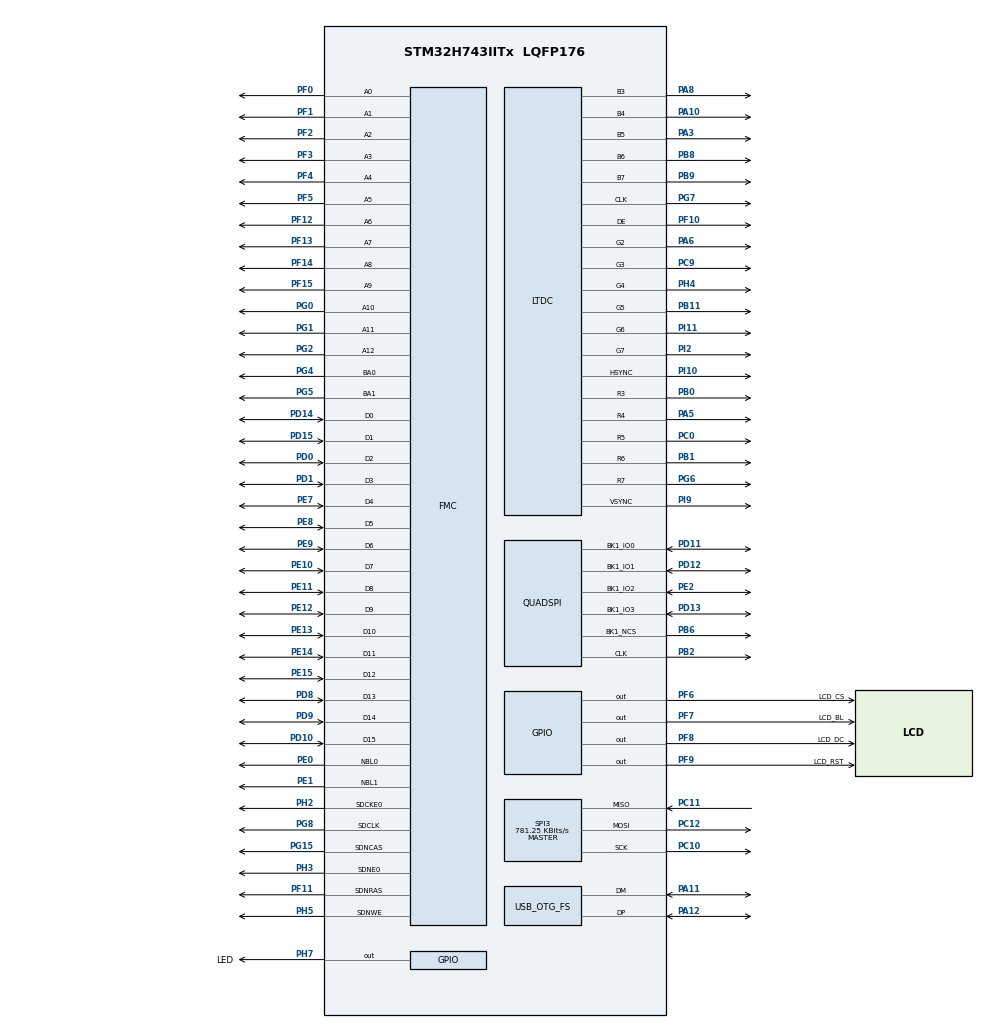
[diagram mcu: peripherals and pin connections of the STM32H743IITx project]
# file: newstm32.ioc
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CORTEX_M7.AccessPermission_Spec=MPU_REGION_FULL_ACCESS
CORTEX_M7.BaseAddress_Spec=0xC0000000
CORTEX_M7.CPU_DCache=Enabled
CORTEX_M7.CPU_ICache=Enabled
CORTEX_M7.DisableExec_Spec=MPU_INSTRUCTION_ACCESS_ENABLE
CORTEX_M7.IsBufferable_Spec=MPU_ACCESS_BUFFERABLE
CORTEX_M7.IsCacheable_Spec=MPU_ACCESS_CACHEABLE
CORTEX_M7.IsShareable_Spec=MPU_ACCESS_NOT_SHAREABLE
CORTEX_M7.Size_Spec=MPU_REGION_SIZE_32MB
CORTEX_M7.SubRegionDisable_Spec=0x0
CORTEX_M7.default_mode_Activation=1
FMC.CASLatency1=FMC_SDRAM_CAS_LATENCY_3
FMC.ExitSelfRefreshDelay1=10
FMC.LoadToActiveDelay1=2
FMC.RCDDelay1=3
FMC.RPDelay1=3
FMC.ReadBurst1=FMC_SDRAM_RBURST_ENABLE
FMC.ReadPipeDelay1=FMC_SDRAM_RPIPE_DELAY_2
FMC.RowCycleDelay1=9
FMC.SDClockPeriod1=FMC_SDRAM_CLOCK_PERIOD_3
FMC.SDClockPeriod2=FMC_SDRAM_CLOCK_PERIOD_3
FMC.SelfRefreshTime1=6
FMC.WriteRecoveryTime1=4
LTDC.ActiveW=320
LTDC.Alpha0_L0=255
LTDC.Alpha_L0=255
LTDC.FBStartAdress_L0=0xC0000000
LTDC.HBP=3
LTDC.HFP=3
LTDC.HSync=3
LTDC.ImageHeight_L0=480
LTDC.ImageWidth_L0=320
LTDC.Layers=0
LTDC.PCPolarity=LTDC_PCPOLARITY_IIPC
LTDC.PixelFormat_L0=LTDC_PIXEL_FORMAT_RGB565
LTDC.VSync=1
LTDC.WindowX1_L0=320
LTDC.WindowY1_L0=480
Mcu.Family=STM32H7
Mcu.Name=STM32H743IITx
Mcu.Package=LQFP176
NVIC.LTDC_IRQn=true\:0\:0\:false\:false\:true\:true\:true\:true
NVIC.OTG_FS_IRQn=true\:0\:0\:false\:false\:true\:false\:true\:true
NVIC.PriorityGroup=NVIC_PRIORITYGROUP_4
PA10.GPIO_Speed=GPIO_SPEED_FREQ_VERY_HIGH
PA10.Mode=RGB565
PA10.Signal=LTDC_B4
PA11.Mode=Device_Only
PA11.Signal=USB_OTG_FS_DM
PA12.Mode=Device_Only
PA12.Signal=USB_OTG_FS_DP
PA3.GPIO_Speed=GPIO_SPEED_FREQ_VERY_HIGH
PA3.Mode=RGB565
PA3.Signal=LTDC_B5
PA5.GPIO_Speed=GPIO_SPEED_FREQ_VERY_HIGH
PA5.Mode=RGB565
PA5.Signal=LTDC_R4
PA6.GPIO_Speed=GPIO_SPEED_FREQ_VERY_HIGH
PA6.Mode=RGB565
PA6.Signal=LTDC_G2
PA8.GPIO_Speed=GPIO_SPEED_FREQ_VERY_HIGH
PA8.Mode=RGB565
PA8.Signal=LTDC_B3
PB0.GPIO_Speed=GPIO_SPEED_FREQ_VERY_HIGH
PB0.Mode=RGB565
PB0.Signal=LTDC_R3
PB1.GPIO_Speed=GPIO_SPEED_FREQ_VERY_HIGH
PB1.Mode=RGB565
PB1.Signal=LTDC_R6
PB11.GPIO_Speed=GPIO_SPEED_FREQ_VERY_HIGH
PB11.Mode=RGB565
PB11.Signal=LTDC_G5
PB2.GPIO_Speed=GPIO_SPEED_FREQ_VERY_HIGH
PB2.Mode=Single Bank 1
PB2.Signal=QUADSPI_CLK
PB6.GPIO_Speed=GPIO_SPEED_FREQ_VERY_HIGH
PB6.Mode=Single Bank 1
PB6.Signal=QUADSPI_BK1_NCS
PB8.GPIO_Speed=GPIO_SPEED_FREQ_VERY_HIGH
PB8.Mode=RGB565
PB8.Signal=LTDC_B6
PB9.GPIO_Speed=GPIO_SPEED_FREQ_VERY_HIGH
PB9.Mode=RGB565
PB9.Signal=LTDC_B7
PC0.GPIO_Speed=GPIO_SPEED_FREQ_VERY_HIGH
PC0.Mode=RGB565
PC0.Signal=LTDC_R5
PC10.Mode=Full_Duplex_Master
PC10.Signal=SPI3_SCK
PC11.Mode=Full_Duplex_Master
PC11.Signal=SPI3_MISO
PC12.Mode=Full_Duplex_Master
PC12.Signal=SPI3_MOSI
PC14-OSC32_IN\ (OSC32_IN).Mode=LSE-External-Oscillator
PC14-OSC32_IN\ (OSC32_IN).Signal=RCC_OSC32_IN
PC15-OSC32_OUT\ (OSC32_OUT).Mode=LSE-External-Oscillator
PC15-OSC32_OUT\ (OSC32_OUT).Signal=RCC_OSC32_OUT
PC9.GPIO_Speed=GPIO_SPEED_FREQ_VERY_HIGH
PC9.Mode=RGB565
PC9.Signal=LTDC_G3
PD0.Signal=FMC_D2_DA2
PD1.Signal=FMC_D3_DA3
PD10.Signal=FMC_D15_DA15
PD11.GPIO_Speed=GPIO_SPEED_FREQ_VERY_HIGH
PD11.Mode=Single Bank 1
PD11.Signal=QUADSPI_BK1_IO0
PD12.GPIO_Speed=GPIO_SPEED_FREQ_VERY_HIGH
PD12.Mode=Single Bank 1
PD12.Signal=QUADSPI_BK1_IO1
PD13.GPIO_Speed=GPIO_SPEED_FREQ_VERY_HIGH
PD13.Mode=Single Bank 1
PD13.Signal=QUADSPI_BK1_IO3
PD14.Signal=FMC_D0_DA0
PD15.Signal=FMC_D1_DA1
PD8.Signal=FMC_D13_DA13
PD9.Signal=FMC_D14_DA14
PE0.Signal=FMC_NBL0
PE1.Signal=FMC_NBL1
PE10.Signal=FMC_D7_DA7
PE11.Signal=FMC_D8_DA8
PE12.Signal=FMC_D9_DA9
PE13.Signal=FMC_D10_DA10
PE14.Signal=FMC_D11_DA11
PE15.Signal=FMC_D12_DA12
PE2.GPIO_Speed=GPIO_SPEED_FREQ_VERY_HIGH
PE2.Mode=Single Bank 1
PE2.Signal=QUADSPI_BK1_IO2
PE7.Signal=FMC_D4_DA4
PE8.Signal=FMC_D5_DA5
PE9.Signal=FMC_D6_DA6
PF0.Signal=FMC_A0
PF1.Signal=FMC_A1
PF10.GPIO_Speed=GPIO_SPEED_FREQ_VERY_HIGH
PF10.Mode=RGB565
PF10.Signal=LTDC_DE
PF11.Signal=FMC_SDNRAS
PF12.Signal=FMC_A6
PF13.Signal=FMC_A7
PF14.Signal=FMC_A8
PF15.Signal=FMC_A9
PF2.Signal=FMC_A2
PF3.Signal=FMC_A3
PF4.Signal=FMC_A4
PF5.Signal=FMC_A5
PF6.GPIO_Label=LCD_CS
PF6.GPIO_Speed=GPIO_SPEED_FREQ_VERY_HIGH
PF6.Signal=GPIO_Output
PF7.GPIO_Label=LCD_BL
PF7.GPIO_Speed=GPIO_SPEED_FREQ_VERY_HIGH
PF7.PinState=GPIO_PIN_SET
PF7.Signal=GPIO_Output
PF8.GPIO_Label=LCD_DC
PF8.GPIO_Speed=GPIO_SPEED_FREQ_VERY_HIGH
PF8.Signal=GPIO_Output
PF9.GPIO_Label=LCD_RST
PF9.GPIO_Speed=GPIO_SPEED_FREQ_VERY_HIGH
PF9.Signal=GPIO_Output
PG0.Signal=FMC_A10
PG1.Signal=FMC_A11
PG15.Signal=FMC_SDNCAS
PG2.Signal=FMC_A12
PG4.Signal=FMC_A14_BA0
PG5.Signal=FMC_A15_BA1
PG6.GPIO_Speed=GPIO_SPEED_FREQ_VERY_HIGH
PG6.Mode=RGB565
PG6.Signal=LTDC_R7
PG7.GPIO_Speed=GPIO_SPEED_FREQ_VERY_HIGH
PG7.Mode=RGB565
PG7.Signal=LTDC_CLK
PG8.Signal=FMC_SDCLK
PH0-OSC_IN\ (PH0).Mode=HSE-External-Oscillator
PH0-OSC_IN\ (PH0).Signal=RCC_OSC_IN
PH1-OSC_OUT\ (PH1).Mode=HSE-External-Oscillator
PH1-OSC_OUT\ (PH1).Signal=RCC_OSC_OUT
PH2.Mode=SdramChipSelect1_1
PH2.Signal=FMC_SDCKE0
PH3.Mode=SdramChipSelect1_1
PH3.Signal=FMC_SDNE0
PH4.GPIO_Speed=GPIO_SPEED_FREQ_VERY_HIGH
PH4.Mode=RGB565
PH4.Signal=LTDC_G4
PH5.Signal=FMC_SDNWE
PH7.GPIO_Label=LED
PH7.PinState=GPIO_PIN_SET
PH7.Signal=GPIO_Output
PI10.GPIO_Speed=GPIO_SPEED_FREQ_VERY_HIGH
PI10.Mode=RGB565
PI10.Signal=LTDC_HSYNC
PI11.GPIO_Speed=GPIO_SPEED_FREQ_VERY_HIGH
PI11.Mode=RGB565
PI11.Signal=LTDC_G6
PI2.GPIO_Speed=GPIO_SPEED_FREQ_VERY_HIGH
PI2.Mode=RGB565
PI2.Signal=LTDC_G7
PI9.GPIO_Speed=GPIO_SPEED_FREQ_VERY_HIGH
PI9.Mode=RGB565
PI9.Signal=LTDC_VSYNC
ProjectManager.HeapSize=0x2000
ProjectManager.StackSize=0x4000
ProjectManager.TargetToolchain=CMake
RCC.ADCFreq_Value=125000000
RCC.APB1Freq_Value=100000000
RCC.APB2Freq_Value=100000000
RCC.APB3Freq_Value=100000000
RCC.APB4Freq_Value=100000000
RCC.CortexFreq_Value=400000000
RCC.D1PPRE=RCC_APB3_DIV2
RCC.D2PPRE1=RCC_APB1_DIV2
RCC.D2PPRE2=RCC_APB2_DIV2
RCC.D3PPRE=RCC_APB4_DIV2
RCC.DIVM1=2
RCC.DIVM2=2
RCC.DIVM3=1
RCC.DIVN1=64
RCC.DIVN2=20
RCC.DIVN3=6
RCC.DIVQ1=4
RCC.DIVR3=15
RCC.FMCCLockSelection=RCC_FMCCLKSOURCE_PLL2
RCC.HCLKFreq_Value=200000000
RCC.HPRE=RCC_HCLK_DIV2
RCC.PLL2FRACN=0
RCC.PLL3FRACN=0
RCC.PLLFRACN=0
RCC.PLLSourceVirtual=RCC_PLLSOURCE_HSE
RCC.SYSCLKFreq_VALUE=400000000
RCC.SYSCLKSource=RCC_SYSCLKSOURCE_PLLCLK
RCC.USBCLockSelection=RCC_USBCLKSOURCE_HSI48
RCC.USBFreq_Value=48000000
SH.FMC_A0.0=FMC_A0,13b-sda1
SH.FMC_A1.0=FMC_A1,13b-sda1
SH.FMC_A10.0=FMC_A10,13b-sda1
SH.FMC_A11.0=FMC_A11,13b-sda1
SH.FMC_A12.0=FMC_A12,13b-sda1
SH.FMC_A14_BA0.0=FMC_BA0,FourSdramBanks1
SH.FMC_A15_BA1.0=FMC_BA1,FourSdramBanks1
SH.FMC_A2.0=FMC_A2,13b-sda1
SH.FMC_A3.0=FMC_A3,13b-sda1
SH.FMC_A4.0=FMC_A4,13b-sda1
SH.FMC_A5.0=FMC_A5,13b-sda1
SH.FMC_A6.0=FMC_A6,13b-sda1
SH.FMC_A7.0=FMC_A7,13b-sda1
SH.FMC_A8.0=FMC_A8,13b-sda1
SH.FMC_A9.0=FMC_A9,13b-sda1
SH.FMC_D0_DA0.0=FMC_D0,sd-16b-d1
SH.FMC_D10_DA10.0=FMC_D10,sd-16b-d1
SH.FMC_D11_DA11.0=FMC_D11,sd-16b-d1
SH.FMC_D12_DA12.0=FMC_D12,sd-16b-d1
SH.FMC_D13_DA13.0=FMC_D13,sd-16b-d1
SH.FMC_D14_DA14.0=FMC_D14,sd-16b-d1
SH.FMC_D15_DA15.0=FMC_D15,sd-16b-d1
SH.FMC_D1_DA1.0=FMC_D1,sd-16b-d1
SH.FMC_D2_DA2.0=FMC_D2,sd-16b-d1
SH.FMC_D3_DA3.0=FMC_D3,sd-16b-d1
SH.FMC_D4_DA4.0=FMC_D4,sd-16b-d1
SH.FMC_D5_DA5.0=FMC_D5,sd-16b-d1
SH.FMC_D6_DA6.0=FMC_D6,sd-16b-d1
SH.FMC_D7_DA7.0=FMC_D7,sd-16b-d1
SH.FMC_D8_DA8.0=FMC_D8,sd-16b-d1
SH.FMC_D9_DA9.0=FMC_D9,sd-16b-d1
SH.FMC_NBL0.0=FMC_NBL0,Sd2ByteEnable1
SH.FMC_NBL1.0=FMC_NBL1,Sd2ByteEnable1
SH.FMC_SDCLK.0=FMC_SDCLK,13b-sda1
SH.FMC_SDNCAS.0=FMC_SDNCAS,13b-sda1
SH.FMC_SDNRAS.0=FMC_SDNRAS,13b-sda1
SH.FMC_SDNWE.0=FMC_SDNWE,13b-sda1
SPI3.BaudRatePrescaler=SPI_BAUDRATEPRESCALER_256
SPI3.CalculateBaudRate=781.25 KBits/s
SPI3.DataSize=SPI_DATASIZE_8BIT
SPI3.Direction=SPI_DIRECTION_2LINES
SPI3.Mode=SPI_MODE_MASTER
SPI3.NSSPMode=SPI_NSS_PULSE_DISABLE
SPI3.VirtualType=VM_MASTER
USB_DEVICE.CLASS_NAME_FS=CDC
USB_DEVICE.VirtualMode-CDC_FS=Cdc
USB_DEVICE.VirtualModeFS=Cdc_FS
USB_OTG_FS.VirtualMode=Device_Only
VP_MEMORYMAP_VS_MEMORYMAP.Mode=CurAppReg
VP_USB_DEVICE_VS_USB_DEVICE_CDC_FS.Mode=CDC_FS
board=custom

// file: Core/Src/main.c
/* USER CODE BEGIN Header */
/**
 ******************************************************************************
 * @file           : main.c
 * @brief          : Main program body
 ******************************************************************************
 * @attention
 *
 * Copyright (c) 2026 STMicroelectronics.
 * All rights reserved.
 *
 * This software is licensed under terms that can be found in the LICENSE file
 * in the root directory of this software component.
 * If no LICENSE file comes with this software, it is provided AS-IS.
 *
 ******************************************************************************
 */
/* USER CODE END Header */
#include "main.h"
#include "ltdc.h"
#include "quadspi.h"
#include "spi.h"
#include "stm32h7xx_hal.h"
#include "usb_device.h"
#include "gpio.h"
#include "fmc.h"

/* USER CODE BEGIN Includes */
#include "usbd_cdc_if.h"
#include <stdio.h>
#include <string.h>
#include "sdram_util.h"
/* USER CODE END Includes */

/* USER CODE BEGIN PD */

uint16_t *frame_buffers[2] = {
    (uint16_t *)(SDRAM_BASE),                                 // FB1
    (uint16_t *)(SDRAM_BASE + (LCD_WIDTH * LCD_HEIGHT * 2))   // FB2
};

extern void pixmap8x16(uint16_t color, void *out_fb, void *pixmap);
extern void pixmap8x8(uint16_t color, void *out_fb, void *pixmap);

uint8_t current_buffer = 0; // Какой буфер сейчас рисуем

int cursor_x = 0;
int cursor_y = 0;

#include <stdint.h>

#define FB_W 480u
#define FB_H 320u

static inline void dma2d_init_once(void)
{
    // DMA2D clock enable (на H7 это AHB3)
    RCC->AHB3ENR |= RCC_AHB3ENR_DMA2DEN;
    (void)RCC->AHB3ENR; // небольшая задержка на запись

    // На всякий: сбросить/очистить флаги
    DMA2D->CR = 0;
    DMA2D->IFCR = 0x3F; // CTC|CCE|CTE|CAE|CTW|CL
}

static inline void dma2d_fill_rgb565(uint16_t *fb,
                                     uint16_t color,
                                     uint32_t width,
                                     uint32_t height,
                                     uint32_t stride_pixels) // обычно = width
{
    // Ждём, если DMA2D занят
    while (DMA2D->CR & DMA2D_CR_START) { /* spin */ }

    // Очистить флаги
    DMA2D->IFCR = 0x3F;

    // Режим: Register-to-Memory
    DMA2D->CR = (DMA2D->CR & ~DMA2D_CR_MODE) | (0x3u << DMA2D_CR_MODE_Pos);

    // Куда пишем
    DMA2D->OMAR = (uint32_t)fb;

    // Формат выхода: RGB565 (в DMA2D это обычно "2")
    // В H7: 0=ARGB8888, 1=RGB888, 2=RGB565, 3=ARGB1555, 4=ARGB4444
    DMA2D->OPFCCR = 2u;

    // Цвет (для RGB565 достаточно младших 16 бит)
    DMA2D->OCOLR = (uint32_t)color;

    // Output offset: сколько пикселей пропустить в конце каждой строки
    // (stride - width) в ПИКСЕЛЯХ, не в байтах
    DMA2D->OOR = (stride_pixels - width);

    // Размер: NLR = (pixels per line) | (number of lines << 16)
    DMA2D->NLR = (width & 0x3FFFu) | ((height & 0x3FFFu) << 16);

    // Старт
    DMA2D->CR |= DMA2D_CR_START;

    // Ждём завершение (можно и по IRQ)
    while ((DMA2D->ISR & DMA2D_ISR_TCIF) == 0) { /* spin */ }

    // Сбросить TC флаг
    DMA2D->IFCR = DMA2D_IFCR_CTCIF;

    __asm__ volatile("dsb 0xF" ::: "memory"); // чтобы записи точно “дошли” до SDRAM
}

static inline void screen_clear(uint16_t *fb, uint16_t color)
{
    // Пишем 32-битными словами: 0xCCCCCCCC где C = RGB565
    uint32_t *p   = (uint32_t*)fb;
    uint32_t pat  = (uint32_t)color | ((uint32_t)color << 16);

    // 4x stm {r0-r7} = 4 * 8 * 4 = 128 байт за итерацию
    uint32_t cnt  = (FB_W * FB_H * 2u) / 128u;   // для 480x320 => 2400

    __asm__ volatile(
        "mov    r0, %[pat]          \n\t"
        "mov    r1, r0              \n\t"
        "mov    r2, r0              \n\t"
        "mov    r3, r0              \n\t"
        "mov    r4, r0              \n\t"
        "mov    r5, r0              \n\t"
        "mov    r6, r0              \n\t"
        "mov    r7, r0              \n\t"
        "1:                         \n\t"
        "stmia  %[p]!, {r0-r7}      \n\t"
        "stmia  %[p]!, {r0-r7}      \n\t"
        "stmia  %[p]!, {r0-r7}      \n\t"
        "stmia  %[p]!, {r0-r7}      \n\t"
        "subs   %[cnt], %[cnt], #1  \n\t"
        "bne    1b                  \n\t"
        : [p]   "+r"(p),
          [cnt] "+r"(cnt)
        : [pat] "r"(pat)
        : "r0","r1","r2","r3","r4","r5","r6","r7","cc","memory"
    );

    // Для внешней памяти (FMC/SDRAM) часто полезно:
    __asm__ volatile("dsb 0xF" ::: "memory");   // __DSB();
}

/* USER CODE END PD */

void SystemClock_Config(void);
static void MPU_Config(void);
/* USER CODE BEGIN PFP */

void draw_rect(uint16_t *fb,int x, int y, int w, int h, uint16_t color) {

    for (int i = y; i < y + h; i++) {
        // Если строка вне экрана — пропускаем её
        if (i < 0 || i >= 480) continue;

        for (int j = x; j < x + w; j++) {
            // Если пиксель вне строки — пропускаем его
            if (j < 0 || j >= 320) continue;

            fb[i * 320 + j] = color;
        }
    }
}

void draw_char(uint16_t *fb, int x, int y, uint16_t color, uint8_t ch) {
    // Используем твои объявленные переменные
    // Смещение: каждый символ в 8x16 занимает ровно 16 байт
    const uint8_t *char_ptr = &fnt_wang_8x16[ch * 16];

    for (int i = 0; i < 16; i++) {
        uint8_t row = char_ptr[i];

        // Рисуем строку из 8 пикселей
        for (int bit = 0; bit < 8; bit++) {
            // Если бит установлен — рисуем пиксель цвета color
            // Если нет — ничего не делаем (прозрачный фон)
            if (row & (0x80 >> bit)) {
                // ВАЖНО: Проверь, что LCD_WIDTH равен Active Width из настроек LTDC
                fb[(y + i) * 320 -1 + (x + bit)] = color;
            }
        }
    }
}

void print_string(uint16_t *fb, int x, int y, uint16_t color, const char *str) {
    int cur_x = x;
    int cur_y = y;

    while (*str) {
        // 1. Проверяем на символ новой строки
        if (*str == '\n') {
            cur_x = x;      // Возвращаемся к начальному X
            cur_y += 16;    // Переходим на 16 пикселей вниз
            str++;
            continue;
        }

        // 2. Проверяем, не вылезем ли мы за край экрана (320 пикселей)
        if (cur_x > 320 - 8) {
            cur_x = x;      // Перенос по достижении края
            cur_y += 16;
        }

        // 3. Проверяем, не вылезем ли за нижний край (480 пикселей)
        if (cur_y > 480 - 16) {
            break; // Экран кончился
        }

        // 4. Рисуем символ
        draw_char(fb, cur_x, cur_y, color, (uint8_t)*str);

        // 5. Сдвигаемся вправо и к следующему символу
        cur_x += 8;
        str++;
    }
}

/* USER CODE END PFP */

int main(void)
{

  /* MPU Configuration--------------------------------------------------------*/
  MPU_Config();

  /* Enable the CPU Cache */

  /* Enable I-Cache---------------------------------------------------------*/
  //SCB_EnableICache();

  /* Enable D-Cache---------------------------------------------------------*/
 // SCB_EnableDCache();

  /* MCU Configuration--------------------------------------------------------*/

  /* Reset of all peripherals, Initializes the Flash interface and the Systick. */
  HAL_Init();

  /* Configure the system clock */
  SystemClock_Config();

  /* Initialize all configured peripherals */
  MX_GPIO_Init();
  MX_FMC_Init();
  MX_QUADSPI_Init();
  MX_SPI3_Init();
  MX_USB_DEVICE_Init();
  /* USER CODE BEGIN 2 */
	SDRAM_Init_All(&hsdram1);

	HAL_GPIO_WritePin(LCD_RST_GPIO_Port, LCD_RST_Pin, GPIO_PIN_RESET);
	HAL_Delay(50);
	HAL_GPIO_WritePin(LCD_RST_GPIO_Port, LCD_RST_Pin, GPIO_PIN_SET);
	HAL_Delay(150);
	HAL_GPIO_WritePin(LCD_BL_GPIO_Port, LCD_BL_Pin, GPIO_PIN_SET);
	ILI9844_SPI_init();
	MX_LTDC_Init();

	LTDC_LayerCfgTypeDef pLayerCfg = {0};

	// Окно отрисовки (весь экран)
	pLayerCfg.WindowX0 = 0;
	pLayerCfg.WindowX1 = 320; // Ширина
	pLayerCfg.WindowY0 = 0;
	pLayerCfg.WindowY1 = 480; // Высота

	pLayerCfg.PixelFormat = LTDC_PIXEL_FORMAT_RGB565;
	pLayerCfg.Alpha = 255;
	pLayerCfg.Alpha0 = 255; // Обычно фон прозрачный, если слой перекрывает его

	// Правильные факторы смешивания для непрозрачного слоя
	pLayerCfg.BlendingFactor1 = LTDC_BLENDING_FACTOR1_PAxCA;
	pLayerCfg.BlendingFactor2 = LTDC_BLENDING_FACTOR2_PAxCA;

	// Твой проверенный адрес в SDRAM!
	pLayerCfg.FBStartAdress = (uint32_t)frame_buffers[current_buffer];

	pLayerCfg.ImageWidth = 320;
	pLayerCfg.ImageHeight = 480;

	pLayerCfg.Backcolor.Blue = 0;
	pLayerCfg.Backcolor.Green = 0;
	pLayerCfg.Backcolor.Red = 0;

	HAL_LTDC_ConfigLayer(&hltdc, &pLayerCfg, 0);
	// Применяем настройки
	HAL_LTDC_Reload(&hltdc, LTDC_RELOAD_IMMEDIATE);

	//  fb_fill(0x001F);
	// Даем USB пару секунд, чтобы Windows его точно увидела

  /* USER CODE END 2 */

  /* Infinite loop */
  /* USER CODE BEGIN WHILE */

int rect_size = 40;
 uint16_t *draw_fb1 = frame_buffers[0];
    memset(draw_fb1, 0, 320 * 480 * 2);
     uint16_t *draw_fb2 = frame_buffers[1];
    memset(draw_fb2, 0, 320 * 480 * 2);

    uint16_t color = 0xF800; // Красный (RGB565)
    int x = 10;
    int y = 10;
    int dx = 1;
    int dy = 1;

while (1) {
    // 1. Выбираем буфер, который сейчас НЕ отображается (Back Buffer)
    uint8_t back_idx = !current_buffer;
    uint16_t *draw_fb = frame_buffers[back_idx];

    // 2. Очистка экрана (чтобы текст не накладывался друг на друга)
    // Используем memset (быстрее) или простой цикл
   // memset(draw_fb, 0, LCD_WIDTH * LCD_HEIGHT * 2);
//screen_clear(draw_fb, 0x0000);

dma2d_init_once();
dma2d_fill_rgb565(draw_fb, 0x0000, 480, 320, 480);

if (x + rect_size >= LCD_HEIGHT-1 || x <= 0) {
        dx = -dx; // Меняем направление по X
    }
    x += dx;

    if (y + rect_size >= LCD_WIDTH-1 || y <= 0) {
        dy = -dy; // Меняем направление по Y
    }
    y += dy;

draw_rect(draw_fb, x, y, rect_size, rect_size, color);

    // draw_char(draw_fb, 100, 100, 0x07E0, 87);
    // draw_char(draw_fb, 100+8, 100, 0x07E0, 88);
    print_string(draw_fb, 50, 50, 0x07E0, "Hello, STM32H7!\nThis is a test of\nLTDC with double buffering.\nEnjoy coding!");

    // 4. СБРОС КЭША (КРИТИЧНО для STM32H7)
    // CPU записал данные в кэш, нужно вытолкнуть их в SDRAM, чтобы LTDC их увидел
  //  SCB_CleanDCache_by_Addr((uint32_t *)draw_fb, LCD_WIDTH * LCD_HEIGHT * 2);

    // 5. Переключаем адрес в LTDC
    HAL_LTDC_SetAddress_NoReload(&hltdc, (uint32_t)draw_fb, 0);
    HAL_LTDC_Reload(&hltdc, LTDC_RELOAD_VERTICAL_BLANKING);

    // 6. Ждем завершения VSync (когда адрес реально применится)
    while ((hltdc.Instance->SRCR & LTDC_RELOAD_VERTICAL_BLANKING) != 0);

    // 7. Меняем индекс для следующей итерации
    current_buffer = back_idx;

   // HAL_Delay(100);
}
  /* USER CODE END 3 */
}

void SystemClock_Config(void)
{
  RCC_OscInitTypeDef RCC_OscInitStruct = {0};
  RCC_ClkInitTypeDef RCC_ClkInitStruct = {0};

  /** Supply configuration update enable
  */
  HAL_PWREx_ConfigSupply(PWR_LDO_SUPPLY);

  /** Configure the main internal regulator output voltage
  */
  __HAL_PWR_VOLTAGESCALING_CONFIG(PWR_REGULATOR_VOLTAGE_SCALE1);

  while(!__HAL_PWR_GET_FLAG(PWR_FLAG_VOSRDY)) {}

  /** Initializes the RCC Oscillators according to the specified parameters
  * in the RCC_OscInitTypeDef structure.
  */
  RCC_OscInitStruct.OscillatorType = RCC_OSCILLATORTYPE_HSI48|RCC_OSCILLATORTYPE_HSE;
  RCC_OscInitStruct.HSEState = RCC_HSE_ON;
  RCC_OscInitStruct.HSI48State = RCC_HSI48_ON;
  RCC_OscInitStruct.PLL.PLLState = RCC_PLL_ON;
  RCC_OscInitStruct.PLL.PLLSource = RCC_PLLSOURCE_HSE;
  RCC_OscInitStruct.PLL.PLLM = 2;
  RCC_OscInitStruct.PLL.PLLN = 64;
  RCC_OscInitStruct.PLL.PLLP = 2;
  RCC_OscInitStruct.PLL.PLLQ = 4;
  RCC_OscInitStruct.PLL.PLLR = 2;
  RCC_OscInitStruct.PLL.PLLRGE = RCC_PLL1VCIRANGE_3;
  RCC_OscInitStruct.PLL.PLLVCOSEL = RCC_PLL1VCOWIDE;
  RCC_OscInitStruct.PLL.PLLFRACN = 0;
  if (HAL_RCC_OscConfig(&RCC_OscInitStruct) != HAL_OK)
  {
    Error_Handler();
  }

  /** Initializes the CPU, AHB and APB buses clocks
  */
  RCC_ClkInitStruct.ClockType = RCC_CLOCKTYPE_HCLK|RCC_CLOCKTYPE_SYSCLK
                              |RCC_CLOCKTYPE_PCLK1|RCC_CLOCKTYPE_PCLK2
                              |RCC_CLOCKTYPE_D3PCLK1|RCC_CLOCKTYPE_D1PCLK1;
  RCC_ClkInitStruct.SYSCLKSource = RCC_SYSCLKSOURCE_PLLCLK;
  RCC_ClkInitStruct.SYSCLKDivider = RCC_SYSCLK_DIV1;
  RCC_ClkInitStruct.AHBCLKDivider = RCC_HCLK_DIV2;
  RCC_ClkInitStruct.APB3CLKDivider = RCC_APB3_DIV2;
  RCC_ClkInitStruct.APB1CLKDivider = RCC_APB1_DIV2;
  RCC_ClkInitStruct.APB2CLKDivider = RCC_APB2_DIV2;
  RCC_ClkInitStruct.APB4CLKDivider = RCC_APB4_DIV2;

  if (HAL_RCC_ClockConfig(&RCC_ClkInitStruct, FLASH_LATENCY_2) != HAL_OK)
  {
    Error_Handler();
  }
}

 /* MPU Configuration */

void MPU_Config(void)
{
  MPU_Region_InitTypeDef MPU_InitStruct = {0};

  /* Disables the MPU */
  HAL_MPU_Disable();

  /** Initializes and configures the Region and the memory to be protected
  */
  MPU_InitStruct.Enable = MPU_REGION_ENABLE;
  MPU_InitStruct.Number = MPU_REGION_NUMBER0;
  MPU_InitStruct.BaseAddress = 0xC0000000;
  MPU_InitStruct.Size = MPU_REGION_SIZE_32MB;
  MPU_InitStruct.SubRegionDisable = 0x0;
  MPU_InitStruct.TypeExtField = MPU_TEX_LEVEL0;
  MPU_InitStruct.AccessPermission = MPU_REGION_FULL_ACCESS;
  MPU_InitStruct.DisableExec = MPU_INSTRUCTION_ACCESS_ENABLE;
  MPU_InitStruct.IsShareable = MPU_ACCESS_NOT_SHAREABLE;
  MPU_InitStruct.IsCacheable = MPU_ACCESS_CACHEABLE;
  MPU_InitStruct.IsBufferable = MPU_ACCESS_BUFFERABLE;

  HAL_MPU_ConfigRegion(&MPU_InitStruct);
  /* Enables the MPU */
  HAL_MPU_Enable(MPU_PRIVILEGED_DEFAULT);

}

void Error_Handler(void)
{
	__disable_irq();
	while (1)
	{
	}
}
